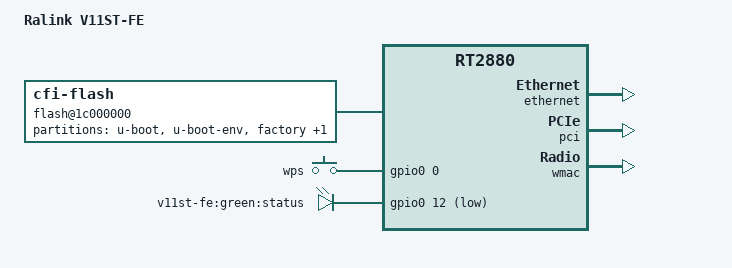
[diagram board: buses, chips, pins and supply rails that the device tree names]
/dts-v1/;

#include "rt2880.dtsi"

#include <dt-bindings/gpio/gpio.h>
#include <dt-bindings/input/input.h>

/ {
	compatible = "ralink,v11st-fe", "ralink,rt2880-soc";
	model = "Ralink V11ST-FE";

	aliases {
		led-boot = &led_status;
		led-failsafe = &led_status;
		led-running = &led_status;
		led-upgrade = &led_status;
	};

	flash@1c000000 {
		compatible = "cfi-flash";
		reg = <0x1c000000 0x800000>;
		bank-width = <2>;

		partitions {
			compatible = "fixed-partitions";
			#address-cells = <1>;
			#size-cells = <1>;

			partition@0 {
				reg = <0x0 0x0030000>;
				label = "u-boot";
				read-only;
			};

			partition@30000 {
				reg = <0x00030000 0x00010000>;
				label = "u-boot-env";
				read-only;
			};

			factory: partition@40000 {
				reg = <0x00040000 0x00010000>;
				label = "factory";
				read-only;
			};

			partition@50000 {
				compatible = "denx,uimage";
				reg = <0x00050000 0x003b0000>;
				label = "firmware";
			};
		};
	};

	keys {
		compatible = "gpio-keys-polled";
		poll-interval = <100>;

		wps {
			label = "wps";
			gpios = <&gpio0 0 GPIO_ACTIVE_HIGH>;
			linux,code = <KEY_WPS_BUTTON>;
		};
	};

	leds {
		compatible = "gpio-leds";

		led_status: status {
			label = "v11st-fe:green:status";
			gpios = <&gpio0 12 GPIO_ACTIVE_LOW>;
		};
	};
};

&gpio0 {
	status = "okay";
};

&ethernet {
	status = "okay";
};

&pci {
	status = "okay";
};

&wmac {
	ralink,mtd-eeprom = <&factory 0x0>;
};
